# HDSC_HC32L130F8UA register map
Vendor: HDSC Co.Ltd; Series: ARMCM0P; File version: 1.2
CPU: CM0 r0p0, little endian, no MPU, no FPU, 3 interrupt priority bits
Registers are 32-bit, read-write, reset 0x0 unless marked. A register's access mark holds for its fields unless they carry their own. Offsets are from the block's base; [hi:lo] are bit positions; {n}, {i} and the like mark numbered series.

## GPIO
Base 0x40020C00
0x08 PA02_SEL
  [2:0] SEL
{0x0+4i} PA{i:02}_SEL (i=4..15)
  [2:0] SEL
0x40 PB00_SEL
  [2:0] SEL
0x44 PB01_SEL
  [2:0] SEL
{0x40+4i} PB{i:02}_SEL (i=3..7)
  [2:0] SEL
0x6C PB11_SEL
  [2:0] SEL
0xB8 PC14_SEL
  [2:0] SEL
0xBC PC15_SEL
  [2:0] SEL
0xC0 PD00_SEL
  [2:0] SEL
0xC4 PD01_SEL
  [2:0] SEL
0xCC PD03_SEL
  [2:0] SEL
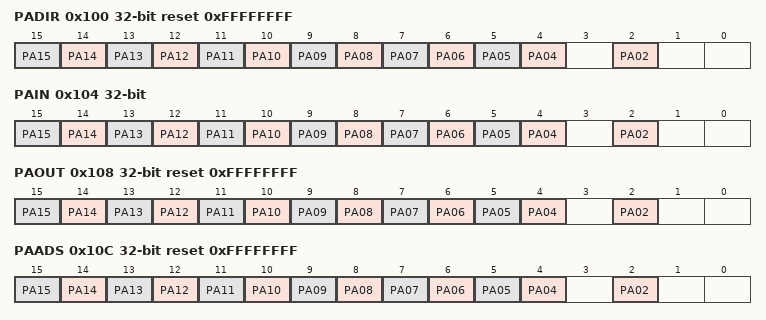
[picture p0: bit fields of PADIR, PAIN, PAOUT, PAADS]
0x100 PADIR reset 0xFFFFFFFF
  [n] PA{n:02} (n=4..15), [2] PA02
0x104 PAIN ro
  [n] PA{n:02} (n=4..15), [2] PA02
0x108 PAOUT reset 0xFFFFFFFF
  [n] PA{n:02} (n=4..15), [2] PA02
0x10C PAADS reset 0xFFFFFFFF
  [n] PA{n:02} (n=4..15), [2] PA02
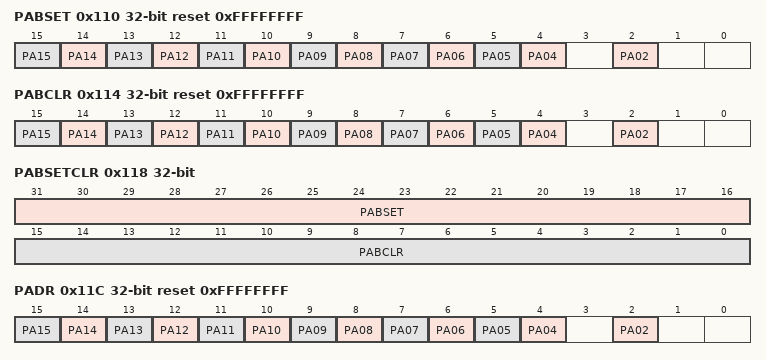
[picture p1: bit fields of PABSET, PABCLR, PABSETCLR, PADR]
0x110 PABSET reset 0xFFFFFFFF
  [n] PA{n:02} (n=4..15), [2] PA02
0x114 PABCLR reset 0xFFFFFFFF
  [n] PA{n:02} (n=4..15), [2] PA02
0x118 PABSETCLR
  [31:16] PABSET, [15:0] PABCLR
0x11C PADR reset 0xFFFFFFFF
  [n] PA{n:02} (n=4..15), [2] PA02
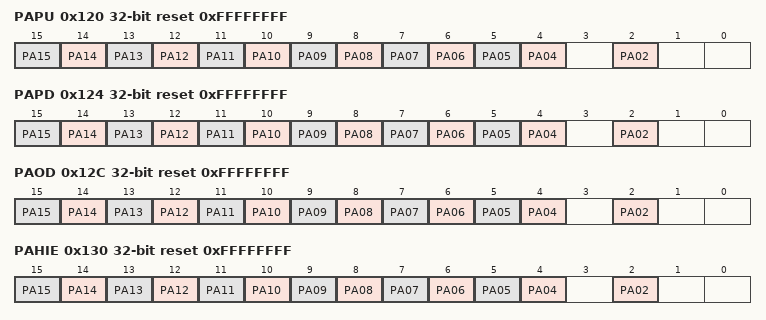
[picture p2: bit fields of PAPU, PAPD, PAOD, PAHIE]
0x120 PAPU reset 0xFFFFFFFF
  [n] PA{n:02} (n=4..15), [2] PA02
0x124 PAPD reset 0xFFFFFFFF
  [n] PA{n:02} (n=4..15), [2] PA02
0x12C PAOD reset 0xFFFFFFFF
  [n] PA{n:02} (n=4..15), [2] PA02
0x130 PAHIE reset 0xFFFFFFFF
  [n] PA{n:02} (n=4..15), [2] PA02
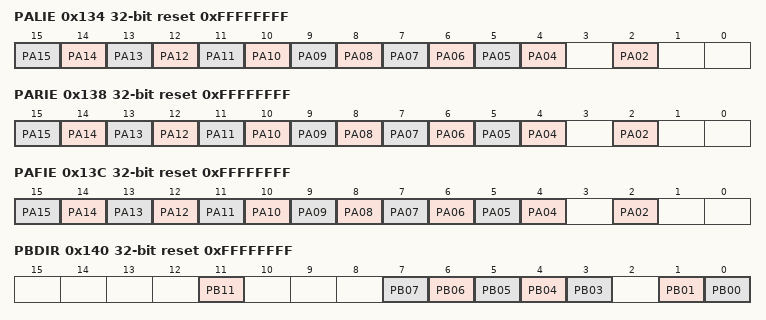
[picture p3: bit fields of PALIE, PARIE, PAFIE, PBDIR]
0x134 PALIE reset 0xFFFFFFFF
  [n] PA{n:02} (n=4..15), [2] PA02
0x138 PARIE reset 0xFFFFFFFF
  [n] PA{n:02} (n=4..15), [2] PA02
0x13C PAFIE reset 0xFFFFFFFF
  [n] PA{n:02} (n=4..15), [2] PA02
0x140 PBDIR reset 0xFFFFFFFF
  [11] PB11, [n] PB{n:02} (n=3..7), [1] PB01, [0] PB00
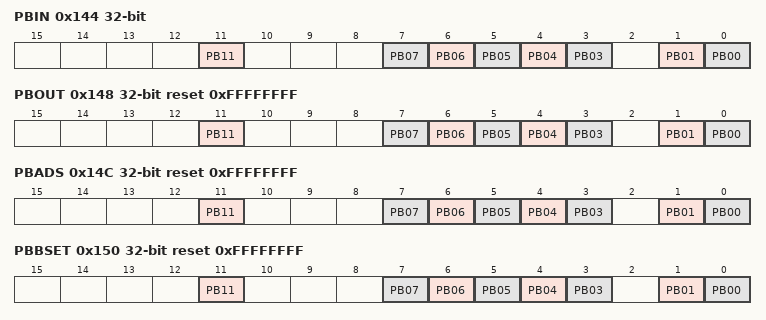
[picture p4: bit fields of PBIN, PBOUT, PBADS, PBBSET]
0x144 PBIN ro
  [11] PB11, [n] PB{n:02} (n=3..7), [1] PB01, [0] PB00
0x148 PBOUT reset 0xFFFFFFFF
  [11] PB11, [n] PB{n:02} (n=3..7), [1] PB01, [0] PB00
0x14C PBADS reset 0xFFFFFFFF
  [11] PB11, [n] PB{n:02} (n=3..7), [1] PB01, [0] PB00
0x150 PBBSET reset 0xFFFFFFFF
  [11] PB11, [n] PB{n:02} (n=3..7), [1] PB01, [0] PB00
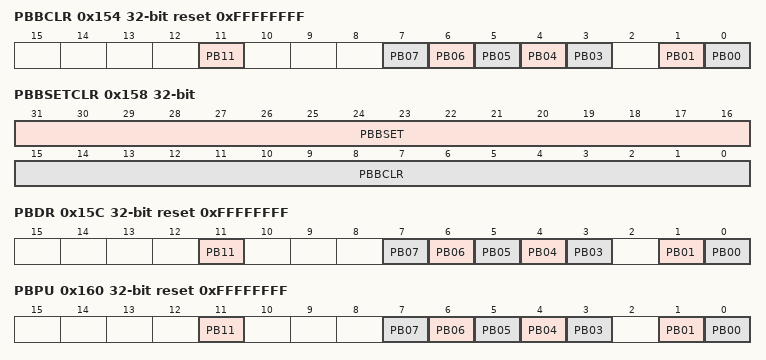
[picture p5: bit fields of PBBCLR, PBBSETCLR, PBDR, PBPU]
0x154 PBBCLR reset 0xFFFFFFFF
  [11] PB11, [n] PB{n:02} (n=3..7), [1] PB01, [0] PB00
0x158 PBBSETCLR
  [31:16] PBBSET, [15:0] PBBCLR
0x15C PBDR reset 0xFFFFFFFF
  [11] PB11, [n] PB{n:02} (n=3..7), [1] PB01, [0] PB00
0x160 PBPU reset 0xFFFFFFFF
  [11] PB11, [n] PB{n:02} (n=3..7), [1] PB01, [0] PB00
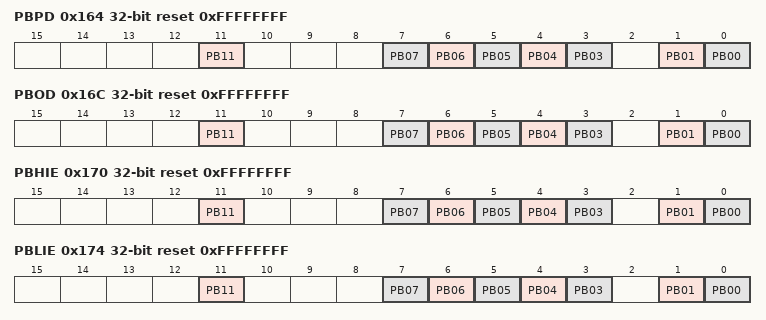
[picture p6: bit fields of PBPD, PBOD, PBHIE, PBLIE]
0x164 PBPD reset 0xFFFFFFFF
  [11] PB11, [n] PB{n:02} (n=3..7), [1] PB01, [0] PB00
0x16C PBOD reset 0xFFFFFFFF
  [11] PB11, [n] PB{n:02} (n=3..7), [1] PB01, [0] PB00
0x170 PBHIE reset 0xFFFFFFFF
  [11] PB11, [n] PB{n:02} (n=3..7), [1] PB01, [0] PB00
0x174 PBLIE reset 0xFFFFFFFF
  [11] PB11, [n] PB{n:02} (n=3..7), [1] PB01, [0] PB00
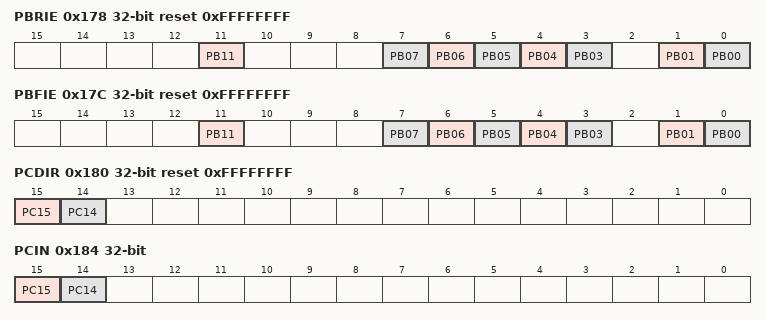
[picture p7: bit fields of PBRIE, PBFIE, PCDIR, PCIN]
0x178 PBRIE reset 0xFFFFFFFF
  [11] PB11, [n] PB{n:02} (n=3..7), [1] PB01, [0] PB00
0x17C PBFIE reset 0xFFFFFFFF
  [11] PB11, [n] PB{n:02} (n=3..7), [1] PB01, [0] PB00
0x180 PCDIR reset 0xFFFFFFFF
  [15] PC15, [14] PC14
0x184 PCIN ro
  [15] PC15, [14] PC14
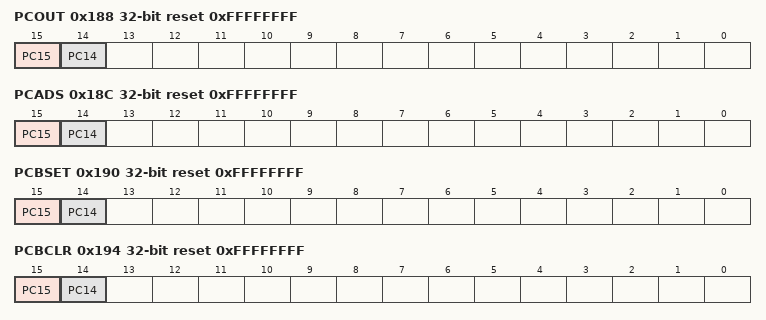
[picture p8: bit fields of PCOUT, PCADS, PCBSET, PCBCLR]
0x188 PCOUT reset 0xFFFFFFFF
  [15] PC15, [14] PC14
0x18C PCADS reset 0xFFFFFFFF
  [15] PC15, [14] PC14
0x190 PCBSET reset 0xFFFFFFFF
  [15] PC15, [14] PC14
0x194 PCBCLR reset 0xFFFFFFFF
  [15] PC15, [14] PC14
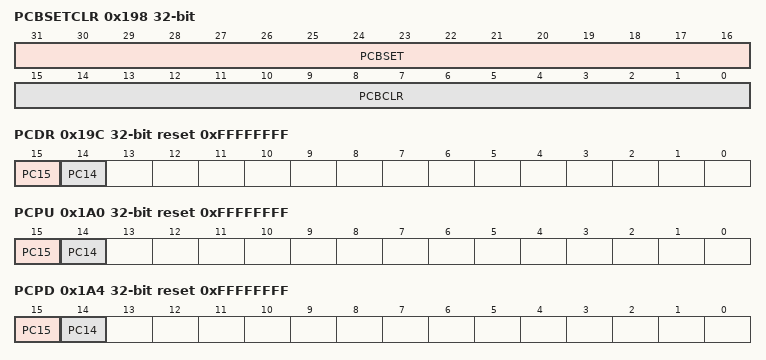
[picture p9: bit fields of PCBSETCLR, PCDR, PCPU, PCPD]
0x198 PCBSETCLR
  [31:16] PCBSET, [15:0] PCBCLR
0x19C PCDR reset 0xFFFFFFFF
  [15] PC15, [14] PC14
0x1A0 PCPU reset 0xFFFFFFFF
  [15] PC15, [14] PC14
0x1A4 PCPD reset 0xFFFFFFFF
  [15] PC15, [14] PC14
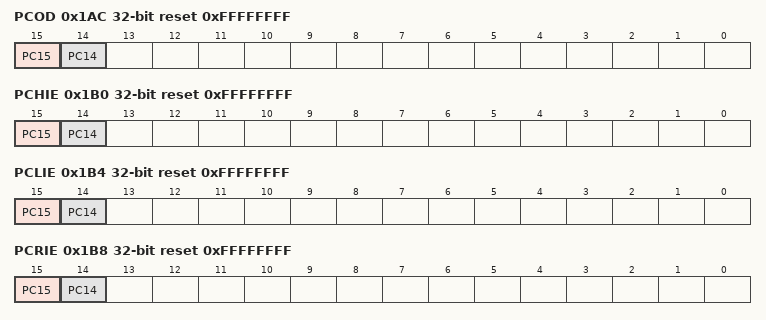
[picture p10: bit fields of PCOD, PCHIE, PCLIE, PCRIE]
0x1AC PCOD reset 0xFFFFFFFF
  [15] PC15, [14] PC14
0x1B0 PCHIE reset 0xFFFFFFFF
  [15] PC15, [14] PC14
0x1B4 PCLIE reset 0xFFFFFFFF
  [15] PC15, [14] PC14
0x1B8 PCRIE reset 0xFFFFFFFF
  [15] PC15, [14] PC14
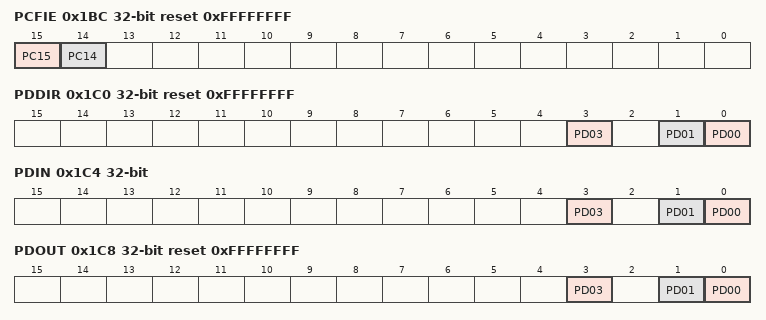
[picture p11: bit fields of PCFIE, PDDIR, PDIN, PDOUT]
0x1BC PCFIE reset 0xFFFFFFFF
  [15] PC15, [14] PC14
0x1C0 PDDIR reset 0xFFFFFFFF
  [3] PD03, [1] PD01, [0] PD00
0x1C4 PDIN ro
  [3] PD03, [1] PD01, [0] PD00
0x1C8 PDOUT reset 0xFFFFFFFF
  [3] PD03, [1] PD01, [0] PD00
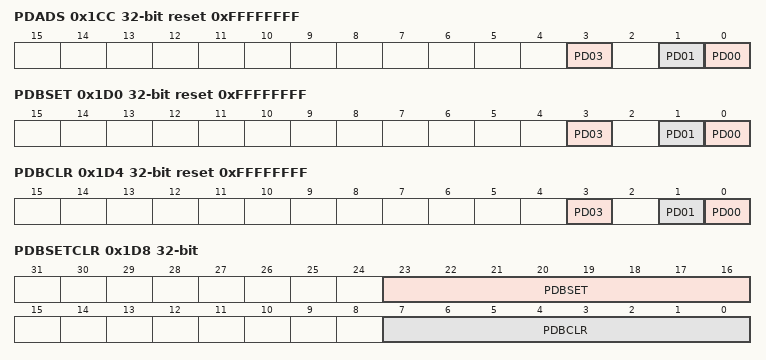
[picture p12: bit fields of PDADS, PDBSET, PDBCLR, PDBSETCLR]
0x1CC PDADS reset 0xFFFFFFFF
  [3] PD03, [1] PD01, [0] PD00
0x1D0 PDBSET reset 0xFFFFFFFF
  [3] PD03, [1] PD01, [0] PD00
0x1D4 PDBCLR reset 0xFFFFFFFF
  [3] PD03, [1] PD01, [0] PD00
0x1D8 PDBSETCLR
  [23:16] PDBSET, [7:0] PDBCLR
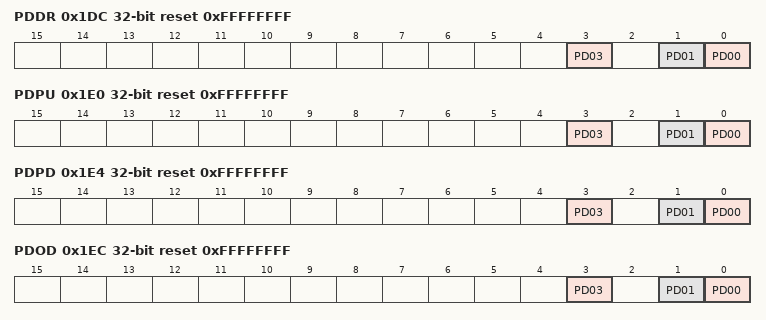
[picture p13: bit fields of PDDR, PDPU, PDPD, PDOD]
0x1DC PDDR reset 0xFFFFFFFF
  [3] PD03, [1] PD01, [0] PD00
0x1E0 PDPU reset 0xFFFFFFFF
  [3] PD03, [1] PD01, [0] PD00
0x1E4 PDPD reset 0xFFFFFFFF
  [3] PD03, [1] PD01, [0] PD00
0x1EC PDOD reset 0xFFFFFFFF
  [3] PD03, [1] PD01, [0] PD00
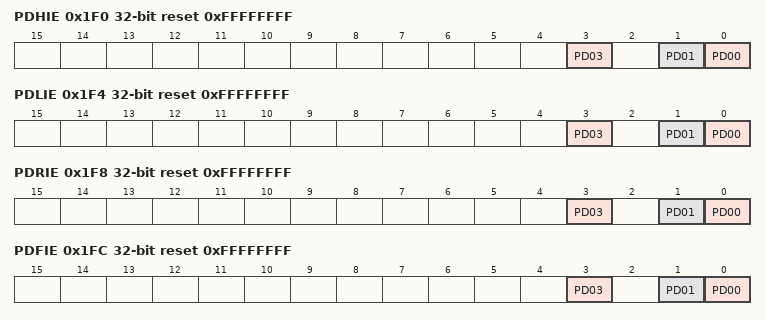
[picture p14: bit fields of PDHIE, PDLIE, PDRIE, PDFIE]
0x1F0 PDHIE reset 0xFFFFFFFF
  [3] PD03, [1] PD01, [0] PD00
0x1F4 PDLIE reset 0xFFFFFFFF
  [3] PD03, [1] PD01, [0] PD00
0x1F8 PDRIE reset 0xFFFFFFFF
  [3] PD03, [1] PD01, [0] PD00
0x1FC PDFIE reset 0xFFFFFFFF
  [3] PD03, [1] PD01, [0] PD00
0x200 PA_STAT ro
  [n] PA{n:02} (n=4..15), [2] PA02
0x210 PA_ICLR reset 0xFFFFFFFF
  [n] PA{n:02} (n=4..15), [2] PA02
0x240 PB_STAT ro
  [11] PB11, [n] PB{n:02} (n=3..7), [1] PB01, [0] PB00
0x250 PB_ICLR reset 0xFFFFFFFF
  [11] PB11, [n] PB{n:02} (n=3..7), [1] PB01, [0] PB00
0x280 PC_STAT ro
  [15] PC15, [14] PC14
0x290 PC_ICLR reset 0xFFFFFFFF
  [15] PC15, [14] PC14
0x2C0 PD_STAT ro
  [3] PD03, [1] PD01, [0] PD00
0x2D0 PD_ICLR reset 0xFFFFFFFF
  [3] PD03, [1] PD01, [0] PD00
0x300 CTRL0 reset 0x1
  [0] IESEL
0x304 CTRL1
  [14] IR_POL, [13] HCLK_EN, [12] PCLK_EN, [11:10] HCLK_SEL, [9:8] PCLK_SEL, [7:4] SSN0_SEL, [3:0] EXT_CLK_SEL
0x308 CTRL2
  [3:0] SSN1_SEL
0x30C TIMGS
  [14:12] LPTIM_G, [3n+2:3n] TIM{n}_G (n=0..3)
0x310 TIMES (reset mask 0xFF)
  [14:12] LPTIM_E, [3n+2:3n] TIM{n}_E (n=0..3)
0x314 TIMCPS (reset mask 0xFF)
  [14:12] TIM3_CB, [3n+2:3n] TIM{n}_CA (n=0..3)
0x318 PCAS (reset mask 0xF)
  [5:3] PCA_ECI, [2:0] PCA_CH0
